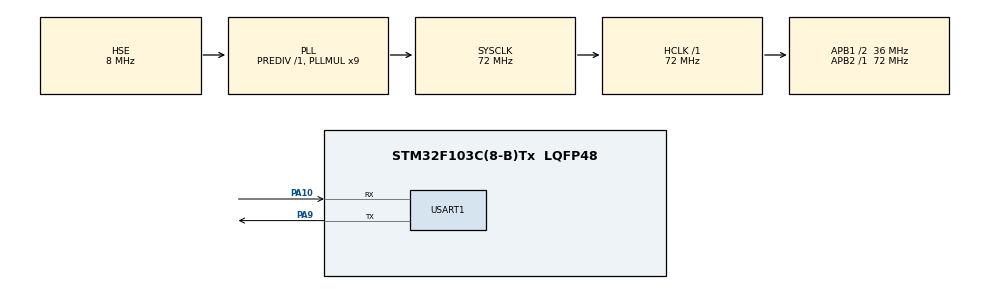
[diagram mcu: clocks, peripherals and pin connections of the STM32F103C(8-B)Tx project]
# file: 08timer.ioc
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Mcu.Family=STM32F1
RCC.PLLSourceVirtual=RCC_PLLSOURCE_HSE
FREERTOS.Tasks01=defaultTask,0,128,StartDefaultTask,Default,NULL,Dynamic,NULL,NULL
PD1-OSC_OUT.Mode=HSE-External-Oscillator
PA10.Mode=Asynchronous
NVIC.TIM1_UP_IRQn=true\:0\:0\:false\:false\:true\:false\:false\:true
PD0-OSC_IN.Signal=RCC_OSC_IN
RCC.APB1CLKDivider=RCC_HCLK_DIV2
RCC.SYSCLKSource=RCC_SYSCLKSOURCE_PLLCLK
ProjectManager.StackSize=0x400
PD1-OSC_OUT.Signal=RCC_OSC_OUT
PA13.Signal=SYS_JTMS-SWDIO
PA9.Mode=Asynchronous
ProjectManager.TargetToolchain=STM32CubeIDE
RCC.HCLKFreq_Value=72000000
RCC.APB2TimFreq_Value=72000000
PA9.Signal=USART1_TX
RCC.USBFreq_Value=72000000
RCC.AHBFreq_Value=72000000
PD0-OSC_IN.Mode=HSE-External-Oscillator
FREERTOS.configUSE_TIMERS=1
board=custom
RCC.PLLMUL=RCC_PLL_MUL9
RCC.APB2Freq_Value=72000000
PA14.Mode=Serial_Wire
VP_SYS_VS_tim1.Mode=TIM1
VP_FREERTOS_VS_CMSIS_V1.Mode=CMSIS_V1
PA13.Mode=Serial_Wire
Mcu.Name=STM32F103C(8-B)Tx
RCC.SYSCLKFreq_VALUE=72000000
Mcu.Package=LQFP48
NVIC.TimeBase=TIM1_UP_IRQn
USART1.VirtualMode=VM_ASYNC
NVIC.TimeBaseIP=TIM1
PA10.Signal=USART1_RX
PA14.Signal=SYS_JTCK-SWCLK
ProjectManager.HeapSize=0x200
FREERTOS.Timers01=myTimer01,Callback01,osTimerPeriodic,Default,NULL,Dynamic,NULL
NVIC.PriorityGroup=NVIC_PRIORITYGROUP_4
RCC.APB1TimFreq_Value=72000000
RCC.APB1Freq_Value=36000000

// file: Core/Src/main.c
/* USER CODE BEGIN Header */
/**
 ******************************************************************************
 * @file           : main.c
 * @brief          : Main program body
 ******************************************************************************
 * @attention
 *
 * <h2><center>&copy; Copyright (c) 2021 STMicroelectronics.
 * All rights reserved.</center></h2>
 *
 * This software component is licensed by ST under BSD 3-Clause license,
 * the "License"; You may not use this file except in compliance with the
 * License. You may obtain a copy of the License at:
 *                        opensource.org/licenses/BSD-3-Clause
 *
 ******************************************************************************
 */
/* USER CODE END Header */
#include "main.h"
#include "cmsis_os.h"

/* USER CODE BEGIN Includes */
#include "stdio.h"
/* USER CODE END Includes */

UART_HandleTypeDef huart1;

osThreadId defaultTaskHandle;
osTimerId myTimer01Handle;

void SystemClock_Config(void);
static void MX_GPIO_Init(void);
static void MX_USART1_UART_Init(void);
void StartDefaultTask(void const *argument);
void Callback01(void const *argument);

/* USER CODE BEGIN 0 */
int _write(int file, char *ptr, int len) {
	HAL_UART_Transmit(&huart1, (uint8_t*) ptr, len, 50);
	return len;
}
/* USER CODE END 0 */

int main(void) {

	/* MCU Configuration--------------------------------------------------------*/

	/* Reset of all peripherals, Initializes the Flash interface and the Systick. */
	HAL_Init();

	/* Configure the system clock */
	SystemClock_Config();

	/* Initialize all configured peripherals */
	MX_GPIO_Init();
	MX_USART1_UART_Init();

	/* Create the timer(s) */
	/* definition and creation of myTimer01 */
	osTimerDef(myTimer01, Callback01);
	myTimer01Handle = osTimerCreate(osTimer(myTimer01), osTimerPeriodic, NULL);

	/* Create the thread(s) */
	/* definition and creation of defaultTask */
	osThreadDef(defaultTask, StartDefaultTask, osPriorityNormal, 0, 128);
	defaultTaskHandle = osThreadCreate(osThread(defaultTask), NULL);

	/* Start scheduler */
	osKernelStart();

	/* We should never get here as control is now taken by the scheduler */
	/* Infinite loop */
	while (1) {

	}
}

void SystemClock_Config(void) {
	RCC_OscInitTypeDef RCC_OscInitStruct = { 0 };
	RCC_ClkInitTypeDef RCC_ClkInitStruct = { 0 };

	/** Initializes the RCC Oscillators according to the specified parameters
	 * in the RCC_OscInitTypeDef structure.
	 */
	RCC_OscInitStruct.OscillatorType = RCC_OSCILLATORTYPE_HSE;
	RCC_OscInitStruct.HSEState = RCC_HSE_ON;
	RCC_OscInitStruct.HSEPredivValue = RCC_HSE_PREDIV_DIV1;
	RCC_OscInitStruct.HSIState = RCC_HSI_ON;
	RCC_OscInitStruct.PLL.PLLState = RCC_PLL_ON;
	RCC_OscInitStruct.PLL.PLLSource = RCC_PLLSOURCE_HSE;
	RCC_OscInitStruct.PLL.PLLMUL = RCC_PLL_MUL9;
	if (HAL_RCC_OscConfig(&RCC_OscInitStruct) != HAL_OK) {
		Error_Handler();
	}
	/** Initializes the CPU, AHB and APB buses clocks
	 */
	RCC_ClkInitStruct.ClockType = RCC_CLOCKTYPE_HCLK | RCC_CLOCKTYPE_SYSCLK
			| RCC_CLOCKTYPE_PCLK1 | RCC_CLOCKTYPE_PCLK2;
	RCC_ClkInitStruct.SYSCLKSource = RCC_SYSCLKSOURCE_PLLCLK;
	RCC_ClkInitStruct.AHBCLKDivider = RCC_SYSCLK_DIV1;
	RCC_ClkInitStruct.APB1CLKDivider = RCC_HCLK_DIV2;
	RCC_ClkInitStruct.APB2CLKDivider = RCC_HCLK_DIV1;

	if (HAL_RCC_ClockConfig(&RCC_ClkInitStruct, FLASH_LATENCY_2) != HAL_OK) {
		Error_Handler();
	}
}

static void MX_USART1_UART_Init(void) {

	huart1.Instance = USART1;
	huart1.Init.BaudRate = 115200;
	huart1.Init.WordLength = UART_WORDLENGTH_8B;
	huart1.Init.StopBits = UART_STOPBITS_1;
	huart1.Init.Parity = UART_PARITY_NONE;
	huart1.Init.Mode = UART_MODE_TX_RX;
	huart1.Init.HwFlowCtl = UART_HWCONTROL_NONE;
	huart1.Init.OverSampling = UART_OVERSAMPLING_16;
	if (HAL_UART_Init(&huart1) != HAL_OK) {
		Error_Handler();
	}

}

static void MX_GPIO_Init(void) {

	/* GPIO Ports Clock Enable */
	__HAL_RCC_GPIOD_CLK_ENABLE();
	__HAL_RCC_GPIOA_CLK_ENABLE();

}

void StartDefaultTask(void const *argument) {
	/* USER CODE BEGIN 5 */
	osTimerStart(myTimer01Handle, 1000);
	/* Infinite loop */
	for (;;) {
		printf("tarea1\n\r");
		osDelay(2000);
	}
	/* USER CODE END 5 */
}

/* Callback01 function */
void Callback01(void const *argument) {
	/* USER CODE BEGIN Callback01 */
	printf("escribiendo el timer\n\r");
	/* USER CODE END Callback01 */
}

void HAL_TIM_PeriodElapsedCallback(TIM_HandleTypeDef *htim) {
	if (htim->Instance == TIM1) {
		HAL_IncTick();
	}
}

void Error_Handler(void) {
	__disable_irq();
	while (1) {
	}
}

/************************ (C) COPYRIGHT STMicroelectronics *****END OF FILE****/
